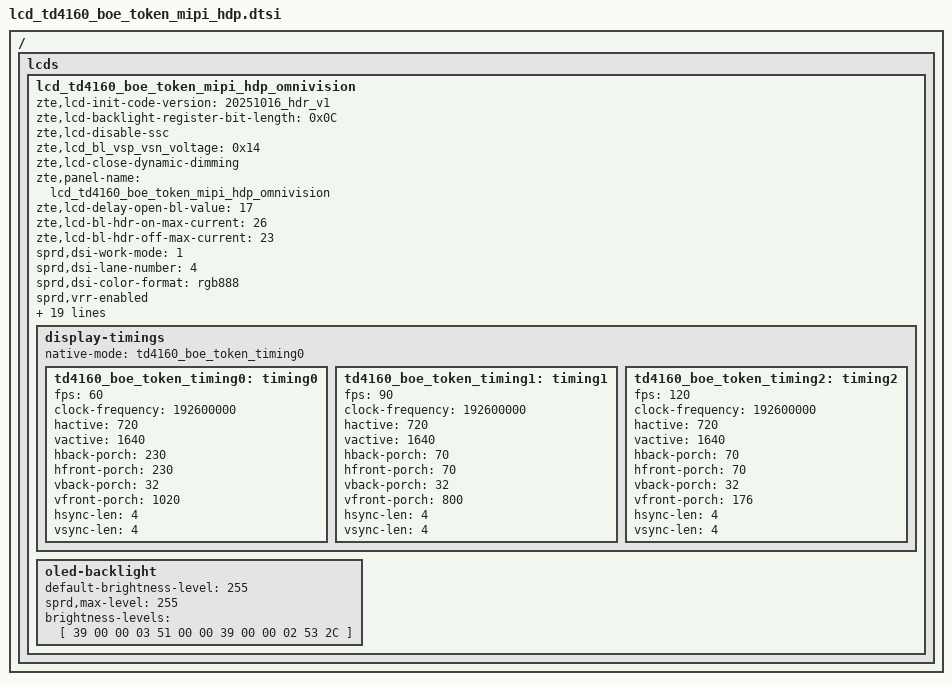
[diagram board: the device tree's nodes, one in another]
// SPDX-License-Identifier: GPL-2.0-only
/*
 * Unisoc td4160 Truly LCD config DTS file
 *
 * Copyright (C) 2021, Unisoc Inc.
 */

/ {
	fragment {
		target-path = "/";
		__overlay__ {
			lcds {
				lcd_td4160_boe_token_mipi_hdp_omnivision: lcd_td4160_boe_token_mipi_hdp_omnivision {
					zte,lcd-init-code-version = "20251016_hdr_v1";
					zte,lcd-backlight-register-bit-length = <0x0C>;
					zte,lcd-disable-ssc;
					zte,lcd_bl_vsp_vsn_voltage = <0x14>;
					zte,lcd-close-dynamic-dimming;
					zte,panel-name = "lcd_td4160_boe_token_mipi_hdp_omnivision";
					zte,lcd-delay-open-bl-value = <17>;
					zte,lcd-bl-hdr-on-max-current = <26>;
					zte,lcd-bl-hdr-off-max-current = <23>;

					sprd,dsi-work-mode = <1>; /* video burst mode*/
					sprd,dsi-lane-number = <4>;
					sprd,dsi-color-format = "rgb888";
					sprd,vrr-enabled;

					sprd,phy-bit-clock = <1155600>;	/* kbps */
					sprd,phy-escape-clock = <20000>;/* kHz */

					sprd,dpi-clk-div = <6>;
					sprd,video-lp-cmd-enable = <1>;
					sprd,hporch-lp-disable = <1>;
					sprd,width-mm = <7026>;/*zte mod for 6.88*/
					sprd,height-mm = <16005>;/*zte mod for 6.88*/
					sprd,esd-check-enable = <0>;
					sprd,esd-check-mode = <0>;
					//sprd,esd-check-register = <0xA>;
					//sprd,esd-check-value = <0x9C>;
					sprd,esd-check-period = <2000>;

					sprd,reset-on-sequence = <1 5>, <0 5>, <1 20>;
					sprd,reset-off-sequence = <1 20>;

					sprd,use-dcs-write;
					sprd,initial-command = [
					23 00 00 02 B0 80
					23 00 00 02 D6 00
					39 00 00 09 B6 30 73 00 06 C3 03 FF FF
					39 00 00 05 B7 35 00 00 00
					39 00 00 07 B8 57 3D 19 BE 1E 0A
					39 00 00 07 B9 6F 3D 28 BE 3C 14
					39 00 00 07 BA B5 33 41 BE 64 23
					39 00 00 0E BE 07 00 00 00 00 00 00 00 00 00 00 00 00
					39 00 00 0F C0 00 36 00 14 06 68 00 00 0A 00 10 00 00 00
					39 00 00 33 C1 30 51 50 FA 01 00 00 10 00 00 00 00 40 0F 00 00 00 00 00 00 00 00 00 00 00 00 00 00 00 00 00 00 00 00 00 00 00 00 00 00 FF F5 84 7A 0A 00 00 00 00 00
					39 00 00 CD C2 04 30 2B 12 09 10 15 10 00 00 04 30 2B 12 09 00 04 10 00 00 04 30 2B 12 00 10 15 10 00 00 00 00 00 00 00 00 00 00 00 00 00 00 00 00 00 00 02 B0 24 10 10 07 09 C9 00 E0 02 08 00 00 00 00 11 00 F0 01 00 00 00 00 00 00 00 00 00 00 00 00 00 00 00 00 00 00 00 00 00 11 00 00 00 00 00 00 00 00 00 00 00 00 00 00 00 00 00 00 00 00 00 00 00 00 11 00 00 00 00 00 00 00 00 00 00 00 00 00 00 00 00 00 00 00 00 00 00 00 00 11 00 00 00 00 00 00 00 00 00 00 00 00 00 00 00 00 00 00 00 00 00 00 00 00 00 00 00 00 00 00 00 00 00 00 00 10 00 00 00 00 00 00 00 00 00 00 00 00 00 00 00 32 00 00 00 00 00 00 00 00 00 00 02 00 00 00
					39 00 00 48 C3 00 00 2B C1 01 50 09 00 00 00 20 00 00 00 2B C1 01 50 09 00 00 00 20 00 00 50 31 C1 01 00 09 00 00 00 20 10 00 50 31 C1 01 00 09 00 00 00 20 00 00 00 00 08 00 00 00 00 00 00 00 00 00 00 00 00 00 00 00 00 00 00 00
					39 00 00 55 C4 00 00 18 0C 10 14 40 42 44 46 48 4A 4C 4E 09 00 00 00 00 00 00 00 00 00 00 00 00 00 00 00 00 09 4F 4D 4B 49 47 45 43 41 15 11 0C 18 00 00 00 00 00 00 00 00 00 00 00 00 00 00 00 00 00 00 00 00 00 00 00 00 00 00 00 00 00 55 55 55 55 55 55 55 55 55 55 55
					39 00 00 29 C6 00 00 00 00 01 22 04 22 01 00 46 0B 01 35 FF 8F 06 C5 02 00 00 00 20 20 00 00 00 C0 11 10 00 01 00 50 00 33 83 00 00 00
					39 00 00 1C CA 00 00 00 00 00 00 00 00 00 00 00 00 00 00 00 00 00 00 00 00 00 E7 11 00 C0 00 00
					39 00 00 0F CB 02 D0 01 80 00 40 00 00 00 00 00 FF 00 04
					39 00 00 1F CE 55 40 49 53 59 5E 63 68 6E 74 7E 8A 98 A8 BB D0 E7 FF 04 00 04 04 42 04 04 62 44 69 5A 44
					23 00 00 02 CF 00
					39 00 00 17 D0 C1 46 81 66 09 90 00 D5 12 1F 11 46 06 7E 09 08 DC 1B F0 06 77 05
					39 00 00 28 D1 CC D4 1B 33 33 17 07 BB 55 55 55 55 00 33 77 07 33 30 06 72 33 13 50 D2 1C 55 32 00 18 70 18 77 11 11 11 20 20 30 55
					39 00 00 04 D2 00 00 A5
					39 00 00 2F D7 01 00 12 12 00 36 00 18 00 36 00 18 03 83 80 85 85 85 87 84 45 86 87 80 88 86 89 83 83 87 84 88 8A 8C 0B 0A EA EA E7 E7 06 06 00 08 0A 0A
					39 00 00 17 D8 40 99 26 ED 16 6C 16 6C 16 6C 00 14 00 14 00 14 01 0C 00 00 01 00
					39 00 00 29 D9 00 02 7F 00 00 00 00 00 00 00 00 00 00 00 00 C0 00 00 00 00 00 00 00 00 00 00 00 00 00 00 00 00 00 00 00 00 00 00 00 00
					39 00 00 05 DD 30 06 23 65
					39 00 00 11 DE 00 00 00 0F FF 00 00 00 40 10 00 00 00 00 00 70
					39 00 00 09 E6 00 00 00 00 00 00 00 00
					39 00 00 1F E7 00 00 00 00 00 00 00 00 00 00 00 00 00 00 00 00 00 00 00 00 00 00 00 00 00 00 00 00 00 00
					39 00 00 15 EB 0A F0 AF 01 42 00 00 CC 0C 08 06 D8 00 00 00 00 00 00 00 00
					39 00 00 03 EC 60 11
					39 00 00 0C ED 00 00 B0 00 02 30 00 00 00 10 00
					39 00 00 76 EE 05 40 05 00 C0 0F 00 C0 0F 00 C0 0f 00 C0 2B 00 C0 0F 00 00 00 00 00 00 03 00 00 00 00 00 00 03 00 00 00 00 00 00 03 00 00 00 00 00 00 03 00 C0 5F 00 00 00 00 00 D5 0F 00 00 00 00 00 00 03 00 00 00 00 00 00 03 00 00 00 00 00 00 03 00 00 03 00 00 03 00 00 03 00 00 03 00 40 15 00 00 00 00 00 14 00 00 00 00 00 00 00 00 00 00 00 00 00 00 00 00 00 00 02
					23 00 00 02 B0 83
					23 00 00 02 B0 80
					39 00 00 03 51 00 00
					 23 00 00 02 53 2c
					 23 00 00 02 55 00
					 23 00 00 02 B0 83
					 23 00 00 02 35 00
					 23 50 00 02 11 00
					 23 14 00 02 29 00
						];

					sprd,sleep-in-command = [
						13 14 00 01 28
						13 78 00 01 10
						];

					sprd,sleep-out-command = [
						13 78 00 01 11
						13 14 00 01 29
						];

					display-timings {
						native-mode = <&td4160_boe_token_timing0>;

						td4160_boe_token_timing0: timing0 {
							fps = <60>;
							clock-frequency = <192600000>;
							hactive = <720>;
							vactive = <1640>;
							hback-porch = <230>;
							hfront-porch = <230>;
							vback-porch = <32>;
							vfront-porch = <1020>;
							hsync-len = <4>;
							vsync-len = <4>;
						};
						td4160_boe_token_timing1: timing1 {
							fps = <90>;
							clock-frequency = <192600000>;
							hactive = <720>;
							vactive = <1640>;
							hback-porch = <70>;
							hfront-porch = <70>;
							vback-porch = <32>;
							vfront-porch = <800>;
							hsync-len = <4>;
							vsync-len = <4>;
						};
						td4160_boe_token_timing2: timing2 {
							fps = <120>;
							clock-frequency = <192600000>;
							hactive = <720>;
							vactive = <1640>;
							hback-porch = <70>;
							hfront-porch = <70>;
							vback-porch = <32>;
							vfront-porch = <176>;
							hsync-len = <4>;
							vsync-len = <4>;
						};
					};
					oled-backlight {
						default-brightness-level = <255>;
						sprd,max-level = <255>;
						brightness-levels = [
							39 00 00 03 51 00 00
							39 00 00 02 53 2C
						];
					};
				};
			};
		};
	};
};
